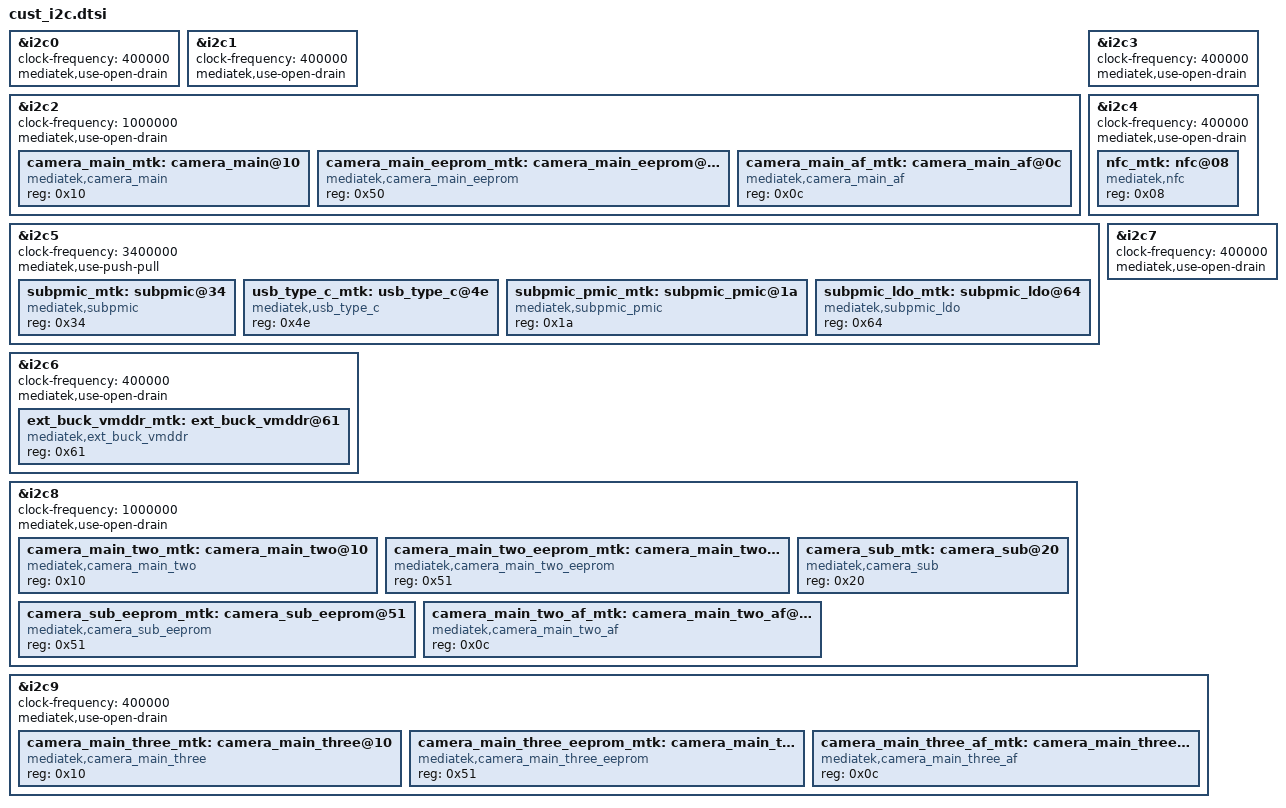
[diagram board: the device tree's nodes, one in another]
/*
 * Generated by MTK SP DrvGen Version: 3.5.160809 for MT6893.
 * 2023-06-02 17:19:58
 * Do Not Modify The File.
 * Copyright Mediatek Inc. (c) 2016.
*/

/*************************
 * I2C DTSI File
*************************/

&i2c0 {
	#address-cells = <1>;
	#size-cells = <0>;
	clock-frequency = <400000>;
	mediatek,use-open-drain;
};

&i2c1 {
	#address-cells = <1>;
	#size-cells = <0>;
	clock-frequency = <400000>;
	mediatek,use-open-drain;
};

&i2c2 {
	#address-cells = <1>;
	#size-cells = <0>;
	clock-frequency = <1000000>;
	mediatek,use-open-drain;
	camera_main_mtk:camera_main@10 {
		compatible = "mediatek,camera_main";
		reg = <0x10>;
		status = "okay";
	};

	camera_main_eeprom_mtk:camera_main_eeprom@50 {
		compatible = "mediatek,camera_main_eeprom";
		reg = <0x50>;
		status = "okay";
	};

	camera_main_af_mtk:camera_main_af@0c {
		compatible = "mediatek,camera_main_af";
		reg = <0x0c>;
		status = "okay";
	};

};

&i2c3 {
	#address-cells = <1>;
	#size-cells = <0>;
	clock-frequency = <400000>;
	mediatek,use-open-drain;
};

&i2c4 {
	#address-cells = <1>;
	#size-cells = <0>;
	clock-frequency = <400000>;
	mediatek,use-open-drain;
	nfc_mtk:nfc@08 {
		compatible = "mediatek,nfc";
		reg = <0x08>;
		status = "okay";
	};

};

&i2c5 {
	#address-cells = <1>;
	#size-cells = <0>;
	clock-frequency = <3400000>;
	mediatek,use-push-pull;
	subpmic_mtk:subpmic@34 {
		compatible = "mediatek,subpmic";
		reg = <0x34>;
		status = "okay";
	};

	usb_type_c_mtk:usb_type_c@4e {
		compatible = "mediatek,usb_type_c";
		reg = <0x4e>;
		status = "okay";
	};

	subpmic_pmic_mtk:subpmic_pmic@1a {
		compatible = "mediatek,subpmic_pmic";
		reg = <0x1a>;
		status = "okay";
	};

	subpmic_ldo_mtk:subpmic_ldo@64 {
		compatible = "mediatek,subpmic_ldo";
		reg = <0x64>;
		status = "okay";
	};

};

&i2c6 {
	#address-cells = <1>;
	#size-cells = <0>;
	clock-frequency = <400000>;
	mediatek,use-open-drain;
	ext_buck_vmddr_mtk:ext_buck_vmddr@61 {
		compatible = "mediatek,ext_buck_vmddr";
		reg = <0x61>;
		status = "okay";
	};

};

&i2c7 {
	#address-cells = <1>;
	#size-cells = <0>;
	clock-frequency = <400000>;
	mediatek,use-open-drain;
};

&i2c8 {
	#address-cells = <1>;
	#size-cells = <0>;
	clock-frequency = <1000000>;
	mediatek,use-open-drain;
	camera_main_two_mtk:camera_main_two@10 {
		compatible = "mediatek,camera_main_two";
		reg = <0x10>;
		status = "okay";
	};

	camera_main_two_eeprom_mtk:camera_main_two_eeprom@51 {
		compatible = "mediatek,camera_main_two_eeprom";
		reg = <0x51>;
		status = "okay";
	};

	camera_sub_mtk:camera_sub@20 {
		compatible = "mediatek,camera_sub";
		reg = <0x20>;
		status = "okay";
	};

	camera_sub_eeprom_mtk:camera_sub_eeprom@51 {
		compatible = "mediatek,camera_sub_eeprom";
		reg = <0x51>;
		status = "okay";
	};

	camera_main_two_af_mtk:camera_main_two_af@0c {
		compatible = "mediatek,camera_main_two_af";
		reg = <0x0c>;
		status = "okay";
	};

};

&i2c9 {
	#address-cells = <1>;
	#size-cells = <0>;
	clock-frequency = <400000>;
	mediatek,use-open-drain;
	camera_main_three_mtk:camera_main_three@10 {
		compatible = "mediatek,camera_main_three";
		reg = <0x10>;
		status = "okay";
	};

	camera_main_three_eeprom_mtk:camera_main_three_eeprom@51 {
		compatible = "mediatek,camera_main_three_eeprom";
		reg = <0x51>;
		status = "okay";
	};

	camera_main_three_af_mtk:camera_main_three_af@0c {
		compatible = "mediatek,camera_main_three_af";
		reg = <0x0c>;
		status = "okay";
	};

};

